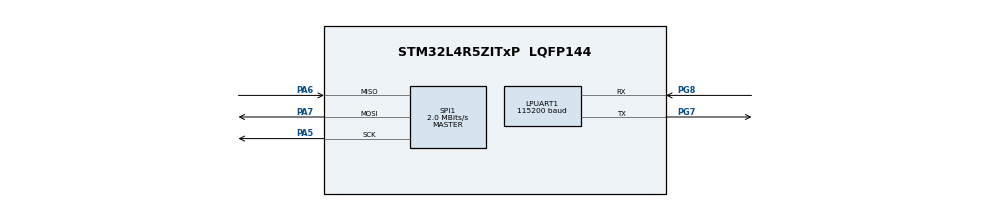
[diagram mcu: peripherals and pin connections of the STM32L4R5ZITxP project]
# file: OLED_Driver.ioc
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LPUART1.BaudRate=115200
LPUART1.WordLength=UART_WORDLENGTH_8B
Mcu.Family=STM32L4
Mcu.Name=STM32L4R5ZITxP
Mcu.Package=LQFP144
NVIC.PriorityGroup=NVIC_PRIORITYGROUP_4
PA0.Signal=S_TIM2_CH1
PA1.Signal=ADCx_IN6
PA10.Signal=USB_OTG_FS_ID
PA13\ (JTMS/SWDIO).Signal=SYS_JTMS-SWDIO
PA14\ (JTCK/SWCLK).Signal=SYS_JTCK-SWCLK
PA3.Signal=ADCx_IN8
PA4.Signal=SPI1_NSS
PA5.Mode=Full_Duplex_Master
PA5.Signal=SPI1_SCK
PA6.Mode=Full_Duplex_Master
PA6.Signal=SPI1_MISO
PA7.Mode=Full_Duplex_Master
PA7.Signal=SPI1_MOSI
PA8.Signal=USB_OTG_FS_SOF
PA9.Signal=USB_OTG_FS_VBUS
PB0.Signal=S_TIM3_CH3
PB1.Signal=ADCx_IN16
PB10.Signal=S_TIM2_CH3
PB12.Signal=SAI2_FS_A
PB13.Signal=SAI2_SCK_A
PB14.Signal=S_TIM15_CH1
PB15.Signal=SAI2_SD_A
PB2.Signal=COMP1_INP
PB3\ (JTDO/TRACESWO).Signal=SPI3_SCK
PB4\ (NJTRST).Signal=SPI3_MISO
PB5.Signal=SPI3_MOSI
PB6.Signal=COMP2_INP
PB8.Signal=I2C1_SCL
PB9.Signal=I2C1_SDA
PC0.Signal=ADCx_IN1
PC1.Signal=ADCx_IN2
PC10.Signal=SDMMC1_D2
PC11.Signal=SDMMC1_D3
PC12.Signal=SDMMC1_CK
PC13.Signal=SYS_WKUP2
PC14-OSC32_IN\ (PC14).Signal=RCC_OSC32_IN
PC15-OSC32_OUT\ (PC15).Signal=RCC_OSC32_OUT
PC2.Signal=ADCx_IN3
PC3.Signal=ADCx_IN4
PC4.Signal=ADCx_IN13
PC5.Signal=ADCx_IN14
PC6.Signal=SAI2_MCLK_A
PC7.Signal=S_TIM3_CH2
PC8.Signal=SDMMC1_D0
PC9.Signal=SDMMC1_D1
PD0.Signal=CAN1_RX
PD14.Signal=S_TIM4_CH3
PD15.Signal=S_TIM4_CH4
PD2.Signal=SDMMC1_CMD
PD3.Signal=USART2_CTS
PD4.Signal=USART2_RTS
PD5.Signal=USART2_TX
PD6.Signal=USART2_RX
PD8.Signal=USART3_TX
PD9.Signal=USART3_RX
PE0.Signal=S_TIM4_ETR
PE10.Signal=TIM1_CH2N
PE11.Signal=S_TIM1_CH2
PE12.Signal=TIM1_CH3N
PE13.Signal=S_TIM1_CH3
PE14.Signal=TIM1_BKIN2
PE15.Signal=TIM1_BKIN
PE2.Signal=SAI1_MCLK_A
PE3.Signal=SAI1_SD_B
PE7.Signal=S_TIM1_ETR
PE8.Signal=TIM1_CH1N
PE9.Signal=S_TIM1_CH1
PF0.Signal=I2C2_SDA
PF1.Signal=I2C2_SCL
PF2.Signal=I2C2_SMBA
PF7.Signal=SAI1_MCLK_B
PG7.Mode=Asynchronous
PG7.Signal=LPUART1_TX
PG8.Mode=Asynchronous
PG8.Signal=LPUART1_RX
PH0-OSC_IN\ (PH0).Signal=RCC_OSC_IN
PH1-OSC_OUT\ (PH1).Signal=RCC_OSC_OUT
ProjectManager.HeapSize=0x200
ProjectManager.StackSize=0x400
ProjectManager.TargetToolchain=STM32CubeIDE
RCC.HSE_VALUE=8000000
RCC.HSI48_VALUE=48000000
RCC.HSI_VALUE=16000000
RCC.LSE_VALUE=32768
RCC.MSI_VALUE=4000000
RCC.VCOOutputFreq_Value=32000000
SH.ADCx_IN1.0=ADC1_IN1
SH.ADCx_IN13.0=ADC1_IN13
SH.ADCx_IN14.0=ADC1_IN14
SH.ADCx_IN16.0=ADC1_IN16
SH.ADCx_IN2.0=ADC1_IN2
SH.ADCx_IN3.0=ADC1_IN3
SH.ADCx_IN4.0=ADC1_IN4
SH.ADCx_IN6.0=ADC1_IN6
SH.ADCx_IN8.0=ADC1_IN8
SH.S_TIM15_CH1.0=TIM15_CH1
SH.S_TIM1_CH1.0=TIM1_CH1
SH.S_TIM1_CH2.0=TIM1_CH2
SH.S_TIM1_CH3.0=TIM1_CH3
SH.S_TIM1_ETR.0=TIM1_ETR
SH.S_TIM2_CH1.0=TIM2_CH1
SH.S_TIM2_CH3.0=TIM2_CH3
SH.S_TIM3_CH2.0=TIM3_CH2
SH.S_TIM3_CH3.0=TIM3_CH3
SH.S_TIM4_CH3.0=TIM4_CH3
SH.S_TIM4_CH4.0=TIM4_CH4
SH.S_TIM4_ETR.0=TIM4_ETR
SPI1.CalculateBaudRate=2.0 MBits/s
SPI1.Direction=SPI_DIRECTION_2LINES
SPI1.Mode=SPI_MODE_MASTER
SPI1.VirtualType=VM_MASTER
board=NUCLEO-L4R5ZI-P

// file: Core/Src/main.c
/* USER CODE BEGIN Header */
/**
  ******************************************************************************
  * @file           : main.c
  * @brief          : Main program body
  ******************************************************************************
  * @attention
  *
  * Copyright (c) 2025 STMicroelectronics.
  * All rights reserved.
  *
  * This software is licensed under terms that can be found in the LICENSE file
  * in the root directory of this software component.
  * If no LICENSE file comes with this software, it is provided AS-IS.
  *
  ******************************************************************************
  */
/* USER CODE END Header */
#include "main.h"
#include "usart.h"
#include "spi.h"
#include "gpio.h"

/* USER CODE BEGIN Includes */
#include "oled.h"

/* USER CODE END Includes */

/* USER CODE BEGIN PV */
/* current system state for display */
static SystemState_t currentState = SYS_WAIT_FOR_SCAN;
static uint32_t lastStateChange = 0;
static uint8_t animPhase = 0;

/* USER CODE END PV */

void SystemClock_Config(void);

int main(void)
{

  /* MCU Configuration--------------------------------------------------------*/

  /* Reset of all peripherals, Initializes the Flash interface and the Systick. */
  HAL_Init();

  /* Configure the system clock */
  SystemClock_Config();

  /* Initialize all configured peripherals */
  MX_GPIO_Init();
  MX_LPUART1_UART_Init();
  MX_SPI1_Init();
  /* USER CODE BEGIN 2 */
  /* Initialize OLED display (uses hspi1 by default) */
  OLED_Init(&hspi1);
  OLED_ShowState(currentState);

  /* USER CODE END 2 */

  /* Infinite loop */
  while (1)
  {

    /* USER CODE BEGIN 3 */
    /* Simple demo: cycle through states every 4 seconds */
    uint32_t now = HAL_GetTick();
    if(now - lastStateChange > 4000){
      lastStateChange = now;
      currentState = (SystemState_t)((currentState + 1) % 4);
      OLED_ShowState(currentState);
    }
    HAL_Delay(100);
  }
  /* USER CODE END 3 */
}

void SystemClock_Config(void)
{
  RCC_OscInitTypeDef RCC_OscInitStruct = {0};
  RCC_ClkInitTypeDef RCC_ClkInitStruct = {0};

  /** Configure the main internal regulator output voltage
  */
  if (HAL_PWREx_ControlVoltageScaling(PWR_REGULATOR_VOLTAGE_SCALE1) != HAL_OK)
  {
    Error_Handler();
  }

  /** Initializes the RCC Oscillators according to the specified parameters
  * in the RCC_OscInitTypeDef structure.
  */
  RCC_OscInitStruct.OscillatorType = RCC_OSCILLATORTYPE_MSI;
  RCC_OscInitStruct.MSIState = RCC_MSI_ON;
  RCC_OscInitStruct.MSICalibrationValue = 0;
  RCC_OscInitStruct.MSIClockRange = RCC_MSIRANGE_6;
  RCC_OscInitStruct.PLL.PLLState = RCC_PLL_NONE;
  if (HAL_RCC_OscConfig(&RCC_OscInitStruct) != HAL_OK)
  {
    Error_Handler();
  }

  /** Initializes the CPU, AHB and APB buses clocks
  */
  RCC_ClkInitStruct.ClockType = RCC_CLOCKTYPE_HCLK|RCC_CLOCKTYPE_SYSCLK
                              |RCC_CLOCKTYPE_PCLK1|RCC_CLOCKTYPE_PCLK2;
  RCC_ClkInitStruct.SYSCLKSource = RCC_SYSCLKSOURCE_MSI;
  RCC_ClkInitStruct.AHBCLKDivider = RCC_SYSCLK_DIV1;
  RCC_ClkInitStruct.APB1CLKDivider = RCC_HCLK_DIV1;
  RCC_ClkInitStruct.APB2CLKDivider = RCC_HCLK_DIV1;

  if (HAL_RCC_ClockConfig(&RCC_ClkInitStruct, FLASH_LATENCY_0) != HAL_OK)
  {
    Error_Handler();
  }
}

void Error_Handler(void)
{
  __disable_irq();
  while (1)
  {
  }
}
